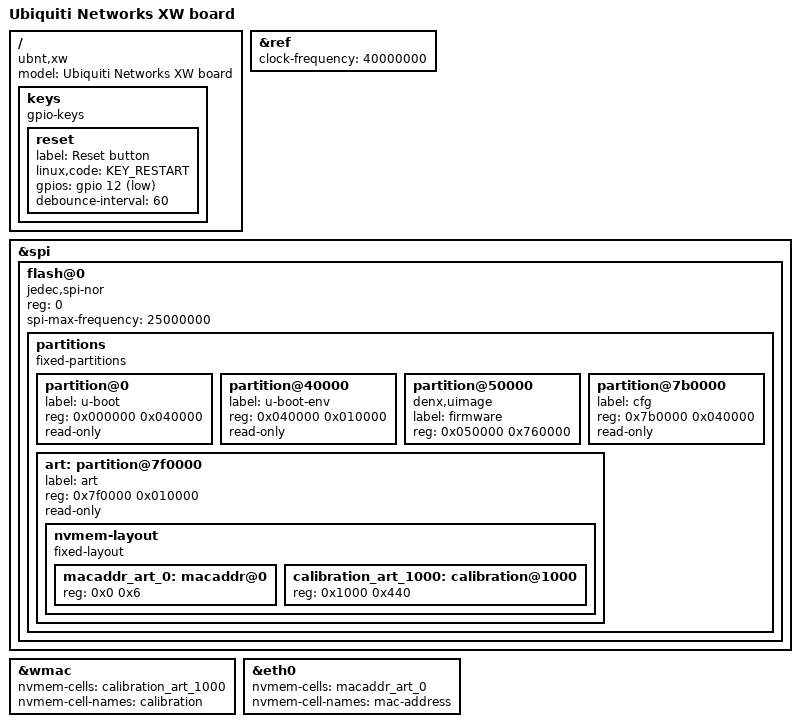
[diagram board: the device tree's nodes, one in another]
// SPDX-License-Identifier: GPL-2.0-or-later OR MIT

#include "ar9344.dtsi"

#include <dt-bindings/gpio/gpio.h>
#include <dt-bindings/input/input.h>

/ {
	compatible = "ubnt,xw", "qca,ar9342";
	model = "Ubiquiti Networks XW board";

	keys {
		compatible = "gpio-keys";

		reset {
			label = "Reset button";
			linux,code = <KEY_RESTART>;
			gpios = <&gpio 12 GPIO_ACTIVE_LOW>;
			debounce-interval = <60>;
		};
	};
};

&ref {
	clock-frequency = <40000000>;
};

&spi {
	status = "okay";

	flash@0 {
		compatible = "jedec,spi-nor";
		reg = <0>;
		spi-max-frequency = <25000000>;

		partitions {
			compatible = "fixed-partitions";
			#address-cells = <1>;
			#size-cells = <1>;

			partition@0 {
				label = "u-boot";
				reg = <0x000000 0x040000>;
				read-only;
			};

			partition@40000 {
				label = "u-boot-env";
				reg = <0x040000 0x010000>;
				read-only;
			};

			partition@50000 {
				compatible = "denx,uimage";
				label = "firmware";
				reg = <0x050000 0x760000>;
			};

			partition@7b0000 {
				label = "cfg";
				reg = <0x7b0000 0x040000>;
				read-only;
			};

			art: partition@7f0000 {
				label = "art";
				reg = <0x7f0000 0x010000>;
				read-only;

				nvmem-layout {
					compatible = "fixed-layout";
					#address-cells = <1>;
					#size-cells = <1>;

					macaddr_art_0: macaddr@0 {
						reg = <0x0 0x6>;
					};

					calibration_art_1000: calibration@1000 {
						reg = <0x1000 0x440>;
					};
				};
			};
		};
	};
};

&wmac {
	status = "okay";

	nvmem-cells = <&calibration_art_1000>;
	nvmem-cell-names = "calibration";
};

&eth0 {
	nvmem-cells = <&macaddr_art_0>;
	nvmem-cell-names = "mac-address";
};
